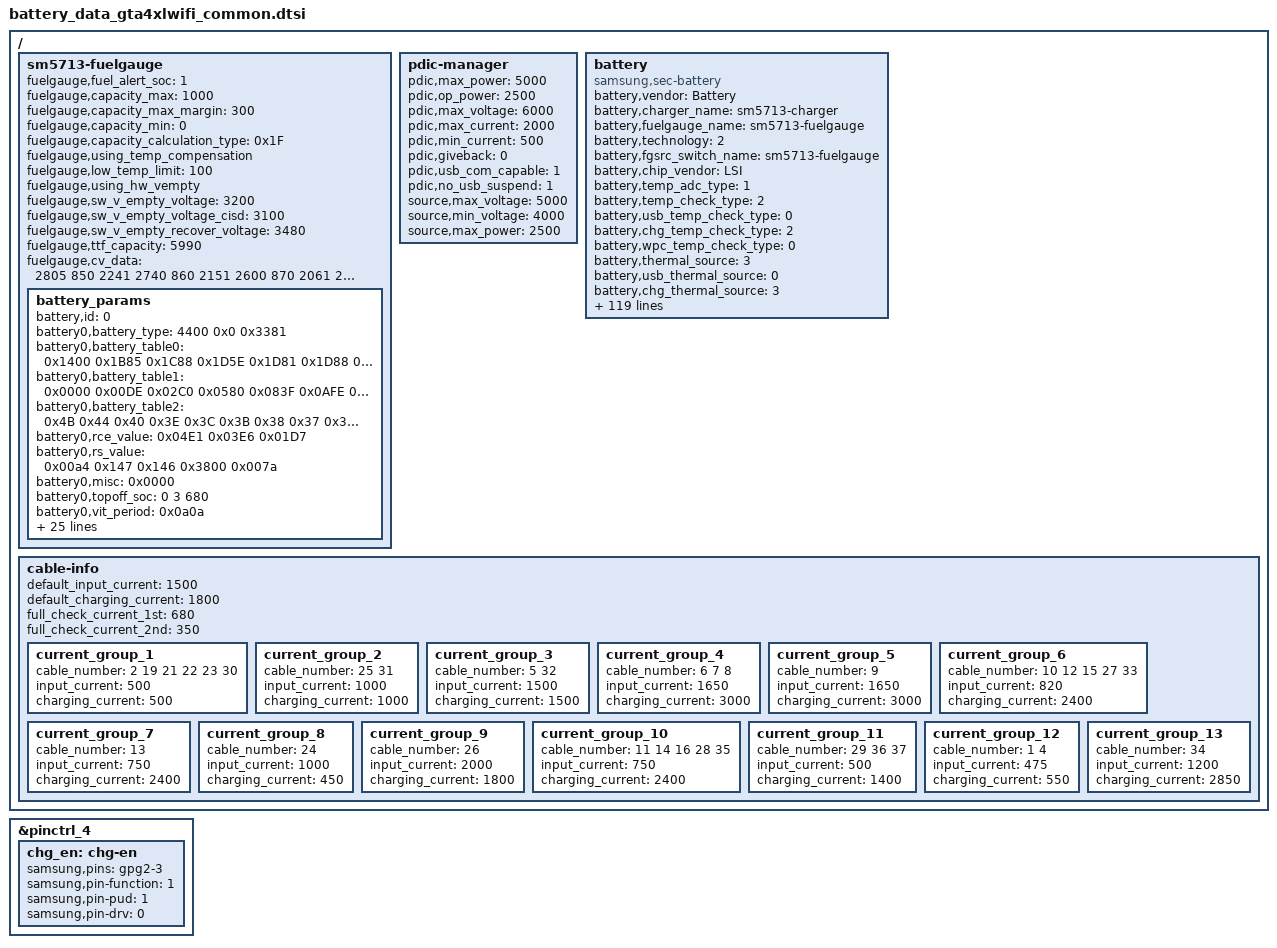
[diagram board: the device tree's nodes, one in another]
/*
 * GTA4XLWIFI battery device tree common
 *
 * Copyright (c) 2019 Samsung Electronics Co., Ltd.
 *		http://www.samsung.com
 *
 * This program is free software; you can redistribute it and/or modify
 * it under the terms of the GNU General Public License version 2 as
 * published by the Free Software Foundation.
 */

/ {
	fragment@battery {
		target-path = "/";
		__overlay__ {
			sm5713-fuelgauge {
				status = "okay";
				fuelgauge,fuel_alert_soc = <1>;
				fuelgauge,capacity_max = <1000>;
				fuelgauge,capacity_max_margin = <300>;
				fuelgauge,capacity_min = <0>;
				fuelgauge,capacity_calculation_type = <0x1F>;
				fuelgauge,using_temp_compensation;
				fuelgauge,low_temp_limit = <100>;
				fuelgauge,using_hw_vempty;
				fuelgauge,sw_v_empty_voltage = <3200>;
				fuelgauge,sw_v_empty_voltage_cisd = <3100>;
				fuelgauge,sw_v_empty_recover_voltage = <3480>;
				fuelgauge,ttf_capacity = <5990>;
				fuelgauge,cv_data = <
						2805	850	2241
						2740	860	2151
						2600	870	2061
						2459	881	1971
						2291	890	1875
						2113	901	1755
						1923	910	1653
						1832	920	1541
						1673	930	1408
						1523	940	1265
						1373	951	1091
						1247	960	941
						1088	970	740
						922	980	522
						980	990	236
						680	1000	0
					>;
				battery_params {
					battery,id = <0>;
					battery0,battery_type = <4400 0x0 0x3381>; /* batt_v_max, min_cap, cap */
					battery0,battery_table0 = <
						0x1400 0x1B85 0x1C88 0x1D5E 0x1D81 0x1D88 0x1DBF 0x1DDB
						0x1DF0 0x1E27 0x1E46 0x1E60 0x1E81 0x1EC5 0x1F06 0x1F80
						0x1FAA 0x1FEB 0x2018 0x2068 0x20C3 0x2127 0x2215 0x2400
						>;
					battery0,battery_table1 = <
						0x0000 0x00DE 0x02C0 0x0580 0x083F 0x0AFE 0x107D 0x133C
						0x15FB 0x1E39 0x23B7 0x2936 0x2EB5 0x36F2 0x3C71 0x41EF
						0x44AF 0x4A2D 0x4CEC 0x4FAC 0x552A 0x5A1C 0x6400 0x6433
						>;
					battery0,battery_table2 = <
						0x4B 0x44 0x40 0x3E 0x3C 0x3B 0x38 0x37
						0x35 0x34 0x34 0x33 0x33 0x33 0x33 0x32
						>;
					battery0,rce_value = <0x04E1 0x03E6 0x01D7>;
					battery0,rs_value = <0x00a4 0x147 0x146 0x3800 0x007a>; /*rs p_mix_factor, n_mix_factor max min*/
					battery0,misc = <0x0000>;
					battery0,topoff_soc = <0 3 680>; /*disable soc*/
					battery0,vit_period = <0x0a0a>;
					battery0,dtcd_value = <0x1>;
					battery0,volt_cal = <0x8000 0x8000>;
					battery0,curr_offset = <1 0 0 0 0 0 0>;
					battery0,mix_value = <0x0103 0x0004>; /*mix_rate init_blank*/
					battery0,temp_std = <25>;
					battery0,temp_cal = <0 6 1 11 (-1) 1 6 1 9 1>;
					battery0,ext_temp_cal = <0 2 1 2 1 1 2 3 2 3>;
					battery0,temp_volcal = <0 15 1>;
					battery0,temp_offset = <1 11 1 1 8 (-1)>;
					battery0,curr_cal = <0x7985 0x7985 0x7985 0x8080 0x8080 0x8080>;
					battery0,tem_poff = <3400 50 3250 50>;
					battery0,arsm = <1 3 1 0x6>;
					battery0,cycle_cfg = <0 0 0>;
					battery0,full_offset = <0 50 0 0xD1 0x90>;
					battery0,age_cntl = <0x325>;
					battery0,tcal_ioff = <0x02 0x30>;
					battery0,v_offset_cancel = <0 0 100 10>;
					battery0,v_alarm = <3100 0>;
					battery0,data_ver = <3>;
					battery0,v_max_table = <0x2215 0x21EA 0x21BF 0x2195 0x2129>;
					battery0,q_max_table = <0x3381 0x31D3 0x30EA 0x3001 0x2DBA>;
					battery0,coeff = <0x2700>;
				};
			};

			pdic-manager {
				/* sink */
				pdic,max_power = <5000>;
				pdic,op_power = <2500>;
				pdic,max_voltage = <6000>;
				pdic,max_current = <2000>;
				pdic,min_current = <500>;

				pdic,giveback = <0>;
				pdic,usb_com_capable = <1>;
				pdic,no_usb_suspend = <1>;

				/* source */
				source,max_voltage = <5000>;
				source,min_voltage = <4000>;
				source,max_power = <2500>;
			};

			battery {
				status = "okay";
				compatible = "samsung,sec-battery";

				pinctrl-names = "default";

				battery,vendor = "Battery";
				battery,charger_name = "sm5713-charger";
				battery,fuelgauge_name = "sm5713-fuelgauge";
				battery,technology = <2>; /* POWER_SUPPLY_TECHNOLOGY_LION */
				battery,fgsrc_switch_name = "sm5713-fuelgauge"; /* Fuelgauge voltage source */

				battery,chip_vendor = "LSI";
				battery,temp_adc_type = <1>; /* SEC_BATTERY_ADC_TYPE_AP */

				battery,temp_check_type = <2>; /* SEC_BATTERY_TEMP_CHECK_TEMP */
				battery,usb_temp_check_type = <0>; /* SEC_BATTERY_TEMP_CHECK_NONE */
				battery,chg_temp_check_type = <2>; /* SEC_BATTERY_TEMP_CHECK_TEMP */
				battery,wpc_temp_check_type = <0>; /* SEC_BATTERY_TEMP_CHECK_NONE */

				battery,thermal_source = <3>; /* SEC_BATTERY_THERMAL_SOURCE_ADC */
				battery,usb_thermal_source = <0>; /* SEC_BATTERY_THERMAL_SOURCE_NONE */
				battery,chg_thermal_source = <3>; /* SEC_BATTERY_THERMAL_SOURCE_ADC */
				battery,wpc_thermal_source = <0>; /* SEC_BATTERY_THERMAL_SOURCE_NONE */

				battery,polling_time = <10 30 30 30 3600>;

				battery,temp_table_adc = <314 364 424 490 571 671 764 909 1051 1220
								1420 1596 1781 2020 2242 2477 2711 2916 3126 3296 
								3443 3538 3666>;
				battery,temp_table_data = <900 850 800 750 700 650 600 550 500 450
								400 350 300 250 200 150 100 50 0 (-50)
								(-100) (-150) (-200)>;

				battery,chg_temp_table_adc = <290 339 415 476 559 657 752 890 1032 1195
								1372 1564 1772 1993 2221 2475 2713 2914 3109 3285 
								3418 3554 3671>;
				battery,chg_temp_table_data = <900 850 800 750 700 650 600 550 500 450
								400 350 300 250 200 150 100 50 0 (-50) 
								(-100) (-150) (-200)>;

				battery,inbat_voltage = <1>;
				battery,inbat_voltage_table_adc = <2817 2803 2783 2753 2728 2701 2680 2654 2628 2597
								2565 2536 2509 2478 2450 2426 2401 2372 2343 2321 2290>;
				battery,inbat_voltage_table_data = <4383 4352 4306 4253 4204 4152 4101 4053 4002 3954
								3903 3852 3801 3750 3702 3654 3601 3552 3503 3456 3402>;

				battery,adc_check_count = <5>;

				battery,cable_check_type = <4>; /* SEC_BATTERY_CABLE_CHECK_PSY */
				battery,cable_source_type = <1>; /* SEC_BATTERY_CABLE_SOURCE_EXTERNAL */
				battery,polling_type = <1>; /* SEC_BATTERY_MONITOR_ALARM */
				battery,monitor_initial_count = <0>;

				battery,battery_check_type = <0>; /* SEC_BATTERY_CHECK_NONE */
				battery,check_count = <0>;
				battery,check_adc_max = <1440>;
				battery,check_adc_min = <0>;

				battery,ovp_uvlo_check_type = <3>; /* SEC_BATTERY_OVP_UVLO_CHGPOLLING */

				battery,temp_check_count = <1>;
				battery,temp_highlimit_threshold_normal = <700>;
				battery,temp_highlimit_recovery_normal = <680>;
				battery,temp_high_threshold_normal = <500>;
				battery,temp_high_recovery_normal = <450>;
				battery,temp_low_threshold_normal = <0>;
				battery,temp_low_recovery_normal = <50>;
				battery,temp_highlimit_threshold_lpm = <700>;
				battery,temp_highlimit_recovery_lpm = <680>;
				battery,temp_high_threshold_lpm = <500>;
				battery,temp_high_recovery_lpm = <450>;
				battery,temp_low_threshold_lpm = <0>;
				battery,temp_low_recovery_lpm = <50>;

				battery,full_check_type = <2>; /* SEC_BATTERY_FULLCHARGED_FG_CURRENT */
				battery,full_check_type_2nd = <2>; /* SEC_BATTERY_FULLCHARGED_FG_CURRENT */
				battery,full_check_count = <1>;
				battery,chg_gpio_full_check = <0>;
				battery,chg_polarity_full_check = <1>;

				battery,chg_heating_prevention_method = <0>; /* SEC_BATTERY_BY_CHANGING_VOLTAGE */
				battery,chg_high_temp = <800>;
				battery,chg_high_temp_recovery = <770>;
				battery,chg_input_limit_current = <1000>;
				battery,chg_charging_limit_current = <1500>;

				battery,store_mode_afc_input_current = <700>;

				battery,sleep_mode_limit_current = <500>;

				battery,mix_high_temp = <410>;
				battery,mix_high_chg_temp = <595>;
				battery,mix_high_temp_recovery = <380>;

				/* SEC_BATTERY_FULL_CONDITION_SOC |
				   SEC_BATTERY_FULL_CONDITION_NOTIMEFULL |
				   SEC_BATTERY_FULL_CONDITION_VCELL */
				battery,full_condition_type = <13>;
				battery,full_condition_soc = <93>;
				battery,full_condition_vcell = <4250>;

				battery,recharge_check_count = <1>;
				battery,recharge_condition_type = <4>; /* SEC_BATTERY_RECHARGE_CONDITION_VCELL */
				battery,recharge_condition_soc = <98>;
				battery,recharge_condition_vcell = <4280>;

				battery,charging_total_time = <14400>;
				battery,hv_charging_total_time = <10800>;
				battery,normal_charging_total_time = <18000>;
				battery,usb_charging_total_time = <36000>;
				battery,recharging_total_time = <5400>;
				battery,charging_reset_time = <0>;

				battery,chg_float_voltage = <4350>;
				battery,chg_ocp_current = <6000>;

				battery,swelling_high_temp_block = <410>;
				battery,swelling_high_temp_recov = <390>;
				battery,swelling_low_temp_block_1st = <150>;
				battery,swelling_low_temp_recov_1st = <200>;
				battery,swelling_low_temp_block_2nd = <50>;
				battery,swelling_low_temp_recov_2nd = <100>;

				battery,swelling_low_temp_current = <1200>;	/* 0.3C */
				battery,swelling_low_temp_current_2nd = <1200>;	/* 0.1C */
				battery,swelling_low_temp_topoff = <350>;	/* 0.05C */
				battery,swelling_high_temp_current = <1800>;	/* 0.45C */
				battery,swelling_high_temp_topoff = <350>;	/* 0.05C */

				battery,swelling_drop_float_voltage = <4150>;
				battery,swelling_high_rechg_voltage = <4000>;
				battery,swelling_low_rechg_voltage = <4000>;
				battery,swelling_drop_float_voltage_lowtemp;

				battery,siop_event_check_type = <1>;
				battery,siop_call_cv_current = <330>;
				battery,siop_call_cc_current = <330>;

				battery,siop_input_limit_current = <1200>;
				battery,siop_charging_limit_current = <1000>;
				battery,siop_hv_input_limit_current = <700>;
				battery,siop_hv_input_limit_current_2nd = <550>;
				battery,siop_hv_charging_limit_current = <1000>;

				battery,ttf_hv_charge_current = <2600>;

				battery,rp_current_rp1 = <500>;
				battery,rp_current_rp2 = <1500>;
				battery,rp_current_rp3 = <3000>;
				battery,rp_current_rdu_rp3 = <2100>;
				battery,rp_current_abnormal_rp3 = <1800>;

				battery,pd_charging_charge_power = <15000>;
				battery,max_charging_current = <3000>;
				battery,max_charging_charge_power = <15000>; /* 15W */
				battery,battery_full_capacity = <7040>;

				/* cycle, chg_float_voltage, recharge_condition_vcell, full_condition_vcell, full_condition_soc */
				battery,age_data = <0 4350 4280 4250 93	/*4.35*/
						300 4330 4260 4230 92	/*4.33*/
						400 4310 4240 4210 91	/*4.31*/
						700 4290 4220 4190 90	/*4.29*/
						1000 4240 4170 4140 89	/*4.24*/
						>;

				battery,health_condition = <
						/* CYCLE ASOC */
						900 0	/* GOOD */
						1200 0 /* NORMAL */
						1500 0 /* AGED */
						>;

				battery,pre_afc_input_current = <500>; /* mA */
				battery,prepare_ta_delay = <0>; /* msec */

				battery,max_input_voltage = <9000>; /* mV */
				battery,max_input_current = <3000>;  /* mA */

				battery,enable_water_resistance;

				battery,standard_curr = <3000>;
				battery,expired_time = <14460>; /* 171 + 70 minutes */
				battery,recharging_expired_time = <5400>;

				battery,cisd_max_voltage_thr = <4400>; /* battery ovp detection voltage */

				battery,cisd_alg_index = <7>;
				battery,ignore_cisd_index = <0 960>;
				battery,ignore_cisd_index_d = <0 120>;

				io-channels = <&exynos_adc 1>, <&exynos_adc 2>, <&exynos_adc 3>;
				io-channel-names = "adc-temp", "adc-in-bat", "adc-chg-temp";
				#io-channel-cells = <5>;
				io-channel-ranges;
			};

		/* sec_battery_cable
		 *   0	UNKNOWN,
		 *   1	NONE,
		 *   2	PREPARE_TA,
		 *   3	TA,
		 *   4	USB,
		 *   5	USB_CDP,
		 *   6	9V_TA,
		 *   7	9V_ERR,
		 *   8	9V_UNKNOWN,
		 *   9	12V_TA,
		 *  10	WIRELESS,
		 *  11	HV_WIRELESS,
		 *  12	PMA_WIRELESS,
		 *  13	WIRELESS_PACK,
		 *  14	WIRELESS_HV_PACK,
		 *  15	WIRELESS_STAND,
		 *  16	WIRELESS_HV_STAND,
		 *  17	QC20,
		 *  18	QC30,
		 *  19	PDIC,
		 *  20	UARTOFF,
		 *  21	OTG,
		 *  22	LAN_HUB,
		 *  23	POWER_SHARING,
		 *  24	HMT_CONNECTED,
		 *  25	HMT_CHARGE,
		 *  26	HV_TA_CHG_LIMIT,
		 *  27	WIRELESS_VEHICLE,
		 *  28	WIRELESS_HV_VEHICLE,
		 *  29	PREPARE_WIRELESS_HV,
		 *  30	TIMEOUT,
		 *  31	SMART_OTG,
		 *  32	SMART_NOTG,
		 *  33	WIRELESS_TX,
		 *  34	HV_WIRELESS_20,
		 *  35	HV_WIRELESS_20_LIMIT,
		 *  36	WIRELESS_FAKE,
		 *  37  PREPARE_WIRELESS_20,
		 *  38	CABLE_PDIC_APDO,
		 *  39	CABLE_MAX,
		 */

			cable-info {
				default_input_current = <1500>;
				default_charging_current = <1800>;
				full_check_current_1st = <680>;
				full_check_current_2nd = <350>;

				current_group_1 {
					cable_number = <2 19 21 22 23 30>;
					input_current = <500>;
					charging_current = <500>;
				};
				current_group_2 {
					cable_number = <25 31>;
					input_current = <1000>;
					charging_current = <1000>;
				};
				current_group_3 {
					cable_number = <5 32>;
					input_current = <1500>;
					charging_current = <1500>;
				};
				current_group_4 {
					cable_number = <6 7 8>;
					input_current = <1650>;
					charging_current = <3000>;
				};
				current_group_5 {
					cable_number = <9>;
					input_current = <1650>;
					charging_current = <3000>;
				};
				current_group_6 {
					cable_number = <10 12 15 27 33>;
					input_current = <820>;
					charging_current = <2400>;
				};
				current_group_7 {
					cable_number = <13>;
					input_current = <750>;
					charging_current = <2400>;
				};
				current_group_8 {
					cable_number = <24>;
					input_current = <1000>;
					charging_current = <450>;
				};
				current_group_9 {
					cable_number = <26>;
					input_current = <2000>;
					charging_current = <1800>;
				};
				current_group_10 {
					cable_number = <11 14 16 28 35>;
					input_current = <750>;
					charging_current = <2400>;
				};
				current_group_11 {
					cable_number = <29 36 37>;
					input_current = <500>;
					charging_current = <1400>;
				};
				current_group_12 {
					cable_number = <1 4>;
					input_current = <475>;
					charging_current = <550>;
				};
				current_group_13 {
					cable_number = <34>;
					input_current = <1200>;
					charging_current = <2850>;
				};
			};
		};
	};
};

&pinctrl_4 {
	chg_en: chg-en {
		samsung,pins = "gpg2-3";
		samsung,pin-function = <1>;
		samsung,pin-pud = <1>;
		samsung,pin-drv = <0>;
	};
};
